AUTOSAR XML (schema 4-2-2)
package /STELLANTIS/EPT/ASWCs
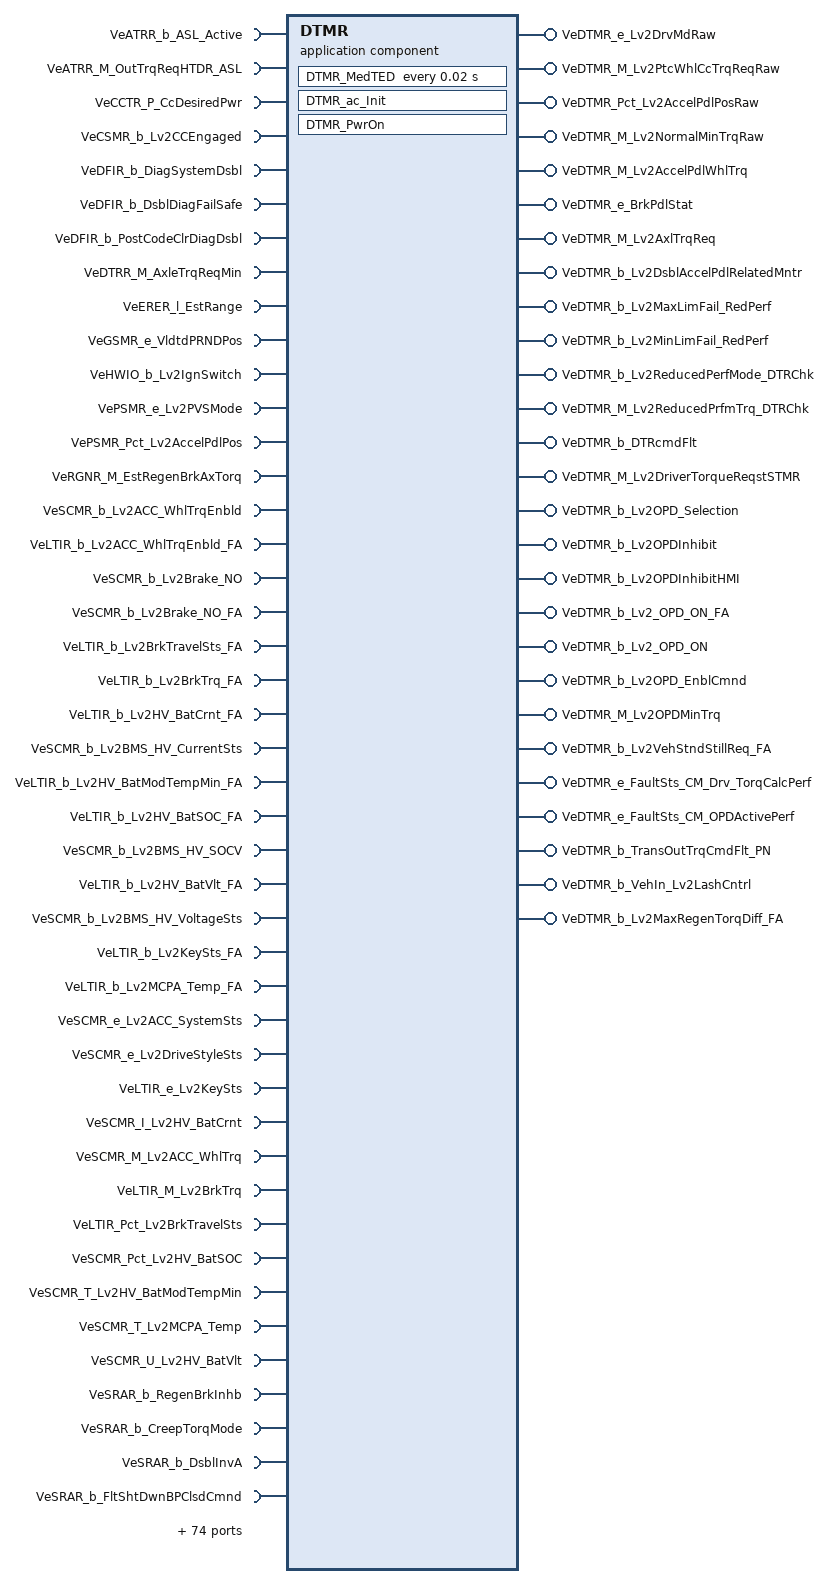
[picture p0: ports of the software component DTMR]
  application sw component type DTMR
    116 x require port:
      VeATRR_b_ASL_Active: nonqueued-receiver-com-spec{data-element=Value, init-value=0}, required-interface=VeATRR_b_ASL_Active
      VeATRR_M_OutTrqReqHTDR_ASL: nonqueued-receiver-com-spec{data-element=Value, init-value=0}, required-interface=VeATRR_M_OutTrqReqHTDR_ASL
      VeCCTR_P_CcDesiredPwr: nonqueued-receiver-com-spec{data-element=Value, init-value=0}, required-interface=VeCCTR_P_CcDesiredPwr
      VeCSMR_b_Lv2CCEngaged: nonqueued-receiver-com-spec{data-element=Value, init-value=0}, required-interface=VeCSMR_b_Lv2CCEngaged
      VeDFIR_b_DiagSystemDsbl: nonqueued-receiver-com-spec{data-element=Value, init-value=0}, required-interface=VeDFIR_b_DiagSystemDsbl
      VeDFIR_b_DsblDiagFailSafe: nonqueued-receiver-com-spec{data-element=Value, init-value=0}, required-interface=VeDFIR_b_DsblDiagFailSafe
      VeDFIR_b_PostCodeClrDiagDsbl: nonqueued-receiver-com-spec{data-element=Value, init-value=0}, required-interface=VeDFIR_b_PostCodeClrDiagDsbl
      VeDTRR_M_AxleTrqReqMin: nonqueued-receiver-com-spec{data-element=Value, init-value=0}, required-interface=VeDTRR_M_AxleTrqReqMin
      VeERER_l_EstRange: nonqueued-receiver-com-spec{data-element=Value, init-value=0}, required-interface=VeERER_l_EstRange
      VeGSMR_e_VldtdPRNDPos: variation-point={short-label=vpVeGSMR_e_VldtdPRNDPos, sw-syscond=1}, nonqueued-receiver-com-spec{data-element=Value, init-value=CeGSMR_e_TransRangePark}, required-interface=VeGSMR_e_VldtdPRNDPos
      VeHWIO_b_Lv2IgnSwitch: nonqueued-receiver-com-spec{data-element=Value, init-value=0}, required-interface=VeHWIO_b_Lv2IgnSwitch
      VePSMR_e_Lv2PVSMode: nonqueued-receiver-com-spec{data-element=Value, init-value=CePSMR_e_NO_Fault}, required-interface=VePSMR_e_Lv2PVSMode
      VePSMR_Pct_Lv2AccelPdlPos: nonqueued-receiver-com-spec{data-element=Value, init-value=0}, required-interface=VePSMR_Pct_Lv2AccelPdlPos
      VeRGNR_M_EstRegenBrkAxTorq: nonqueued-receiver-com-spec{data-element=Value, init-value=0}, required-interface=VeRGNR_M_EstRegenBrkAxTorq
      VeSCMR_b_Lv2ACC_WhlTrqEnbld: nonqueued-receiver-com-spec{data-element=Value, init-value=0}, required-interface=VeSCMR_b_Lv2ACC_WhlTrqEnbld
      VeLTIR_b_Lv2ACC_WhlTrqEnbld_FA: nonqueued-receiver-com-spec{data-element=Value, init-value=0}, required-interface=VeLTIR_b_Lv2ACC_WhlTrqEnbld_FA
      VeSCMR_b_Lv2Brake_NO: nonqueued-receiver-com-spec{data-element=Value, init-value=0}, required-interface=VeSCMR_b_Lv2Brake_NO
      VeSCMR_b_Lv2Brake_NO_FA: nonqueued-receiver-com-spec{data-element=Value, init-value=0}, required-interface=VeSCMR_b_Lv2Brake_NO_FA
      VeLTIR_b_Lv2BrkTravelSts_FA: nonqueued-receiver-com-spec{data-element=Value, init-value=0}, required-interface=VeLTIR_b_Lv2BrkTravelSts_FA
      VeLTIR_b_Lv2BrkTrq_FA: nonqueued-receiver-com-spec{data-element=Value, init-value=0}, required-interface=VeLTIR_b_Lv2BrkTrq_FA
      VeLTIR_b_Lv2HV_BatCrnt_FA: nonqueued-receiver-com-spec{data-element=Value, init-value=0}, required-interface=VeLTIR_b_Lv2HV_BatCrnt_FA
      VeSCMR_b_Lv2BMS_HV_CurrentSts: nonqueued-receiver-com-spec{data-element=Value, init-value=0}, required-interface=VeSCMR_b_Lv2BMS_HV_CurrentSts
      VeLTIR_b_Lv2HV_BatModTempMin_FA: nonqueued-receiver-com-spec{data-element=Value, init-value=0}, required-interface=VeLTIR_b_Lv2HV_BatModTempMin_FA
      VeLTIR_b_Lv2HV_BatSOC_FA: nonqueued-receiver-com-spec{data-element=Value, init-value=0}, required-interface=VeLTIR_b_Lv2HV_BatSOC_FA
      VeSCMR_b_Lv2BMS_HV_SOCV: nonqueued-receiver-com-spec{data-element=Value, init-value=0}, required-interface=VeSCMR_b_Lv2BMS_HV_SOCV
      VeLTIR_b_Lv2HV_BatVlt_FA: nonqueued-receiver-com-spec{data-element=Value, init-value=0}, required-interface=VeLTIR_b_Lv2HV_BatVlt_FA
      VeSCMR_b_Lv2BMS_HV_VoltageSts: nonqueued-receiver-com-spec{data-element=Value, init-value=0}, required-interface=VeSCMR_b_Lv2BMS_HV_VoltageSts
      VeLTIR_b_Lv2KeySts_FA: nonqueued-receiver-com-spec{data-element=Value, init-value=0}, required-interface=VeLTIR_b_Lv2KeySts_FA
      VeLTIR_b_Lv2MCPA_Temp_FA: nonqueued-receiver-com-spec{data-element=Value, init-value=0}, required-interface=VeLTIR_b_Lv2MCPA_Temp_FA
      VeSCMR_e_Lv2ACC_SystemSts: nonqueued-receiver-com-spec{data-element=Value, init-value=CeSTMR_e_Off_M182}, required-interface=VeSCMR_e_Lv2ACC_SystemSts
      VeSCMR_e_Lv2DriveStyleSts: nonqueued-receiver-com-spec{data-element=Value, init-value=0}, required-interface=VeSCMR_e_Lv2DriveStyleSts
      VeLTIR_e_Lv2KeySts: nonqueued-receiver-com-spec{data-element=Value, init-value=CeLTIR_e_IGN_LK}, required-interface=VeLTIR_e_Lv2KeySts
      VeSCMR_I_Lv2HV_BatCrnt: nonqueued-receiver-com-spec{data-element=Value, init-value=0}, required-interface=VeSCMR_I_Lv2HV_BatCrnt
      VeSCMR_M_Lv2ACC_WhlTrq: nonqueued-receiver-com-spec{data-element=Value, init-value=0}, required-interface=VeSCMR_M_Lv2ACC_WhlTrq
      VeLTIR_M_Lv2BrkTrq: nonqueued-receiver-com-spec{data-element=Value, init-value=0}, required-interface=VeLTIR_M_Lv2BrkTrq
      VeLTIR_Pct_Lv2BrkTravelSts: nonqueued-receiver-com-spec{data-element=Value, init-value=0}, required-interface=VeLTIR_Pct_Lv2BrkTravelSts
      VeSCMR_Pct_Lv2HV_BatSOC: nonqueued-receiver-com-spec{data-element=Value, init-value=0}, required-interface=VeSCMR_Pct_Lv2HV_BatSOC
      VeSCMR_T_Lv2HV_BatModTempMin: nonqueued-receiver-com-spec{data-element=Value, init-value=0}, required-interface=VeSCMR_T_Lv2HV_BatModTempMin
      VeSCMR_T_Lv2MCPA_Temp: nonqueued-receiver-com-spec{data-element=Value, init-value=0}, required-interface=VeSCMR_T_Lv2MCPA_Temp
      VeSCMR_U_Lv2HV_BatVlt: nonqueued-receiver-com-spec{data-element=Value, init-value=0}, required-interface=VeSCMR_U_Lv2HV_BatVlt
      VeSRAR_b_RegenBrkInhb: nonqueued-receiver-com-spec{data-element=Value, init-value=0}, required-interface=VeSRAR_b_RegenBrkInhb
      VeSRAR_b_CreepTorqMode: nonqueued-receiver-com-spec{data-element=Value, init-value=0}, required-interface=VeSRAR_b_CreepTorqMode
      VeSRAR_b_DsblInvA: nonqueued-receiver-com-spec{data-element=Value, init-value=0}, required-interface=VeSRAR_b_DsblInvA
      VeSRAR_b_FltShtDwnBPClsdCmnd: nonqueued-receiver-com-spec{data-element=Value, init-value=0}, required-interface=VeSRAR_b_FltShtDwnBPClsdCmnd
      VeSRAR_b_FltShtDwnCmnd: nonqueued-receiver-com-spec{data-element=Value, init-value=0}, required-interface=VeSRAR_b_FltShtDwnCmnd
      VeSRAR_b_OpnBattCntctr: nonqueued-receiver-com-spec{data-element=Value, init-value=0}, required-interface=VeSRAR_b_OpnBattCntctr
      VeSRAR_b_ReducedPerfMode: nonqueued-receiver-com-spec{data-element=Value, init-value=0}, required-interface=VeSRAR_b_ReducedPerfMode
      VeSSMR_b_VehSpdFA: nonqueued-receiver-com-spec{data-element=Value, init-value=0}, required-interface=VeSSMR_b_VehSpdFA
      VeSSMR_v_VehSpd: nonqueued-receiver-com-spec{data-element=Value, init-value=0}, required-interface=VeSSMR_v_VehSpd
      VeSCCR_r_RipAWD: nonqueued-receiver-com-spec{data-element=Value, init-value=0}, required-interface=VeSCCR_r_RipAWD
      VeSCCR_b_PerfAWDFlag: nonqueued-receiver-com-spec{data-element=Value, init-value=0}, required-interface=VeSCCR_b_PerfAWDFlag
      VeSCCR_M_FrntAxlOLMin: nonqueued-receiver-com-spec{data-element=Value, init-value=0}, required-interface=VeSCCR_M_FrntAxlOLMin
      VeSCCR_M_FrntAxlOLMax: nonqueued-receiver-com-spec{data-element=Value, init-value=0}, required-interface=VeSCCR_M_FrntAxlOLMax
      VeSCCR_M_RrAxlOLMax: nonqueued-receiver-com-spec{data-element=Value, init-value=0}, required-interface=VeSCCR_M_RrAxlOLMax
      VeSCCR_M_RrAxlOLMin: nonqueued-receiver-com-spec{data-element=Value, init-value=0}, required-interface=VeSCCR_M_RrAxlOLMin
      VeSCMR_M_Lv2RegenBrkFrontOffsetRequest: nonqueued-receiver-com-spec{data-element=Value, init-value=0}, required-interface=VeSCMR_M_Lv2RegenBrkFrontOffsetRequest
      VeSCMR_M_Lv2RegenBrkRearOffsetRequest: nonqueued-receiver-com-spec{data-element=Value, init-value=0}, required-interface=VeSCMR_M_Lv2RegenBrkRearOffsetRequest
      VeSCMR_b_Lv2RegenBrkFrontOffsetRequestFA: nonqueued-receiver-com-spec{data-element=Value, init-value=0}, required-interface=VeSCMR_b_Lv2RegenBrkFrontOffsetRequestFA
      VeSCMR_b_Lv2RegenBrkRearOffsetRequestFA: nonqueued-receiver-com-spec{data-element=Value, init-value=0}, required-interface=VeSCMR_b_Lv2RegenBrkRearOffsetRequestFA
      VeSCMR_b_Lv2ESC_Active: nonqueued-receiver-com-spec{data-element=Value, init-value=0}, required-interface=VeSCMR_b_Lv2ESC_Active
      VeSCMR_b_Lv2ESC_FailSts: nonqueued-receiver-com-spec{data-element=Value, init-value=0}, required-interface=VeSCMR_b_Lv2ESC_FailSts
      VeDMIR_e_eCoastingSel: nonqueued-receiver-com-spec{data-element=Value, init-value=CeDMIR_e_Level1}, required-interface=VeDMIR_e_eCoastingSel
      VeSCMR_b_RegBrk_Active: nonqueued-receiver-com-spec{data-element=Value, init-value=0}, required-interface=VeSCMR_b_RegBrk_Active
      VeSCCR_r_RipRegen: nonqueued-receiver-com-spec{data-element=Value, init-value=0}, required-interface=VeSCCR_r_RipRegen
      VeVTVR_M_OptToFront: nonqueued-receiver-com-spec{data-element=Value, init-value=0}, required-interface=VeVTVR_M_OptToFront
      VeVTVR_M_OptToRear: nonqueued-receiver-com-spec{data-element=Value, init-value=0}, required-interface=VeVTVR_M_OptToRear
      VeATRR_M_OutputTorqReqImmedHTDR: nonqueued-receiver-com-spec{data-element=Value, init-value=0}, required-interface=VeATRR_M_OutputTorqReqImmedHTDR
      VeSTMR_b_Lv2STMR_ReducedPerfMode: nonqueued-receiver-com-spec{data-element=Value, init-value=0}, required-interface=VeSTMR_b_Lv2STMR_ReducedPerfMode
      VeSTMR_b_TransOutTrqCmdFlt: nonqueued-receiver-com-spec{data-element=Value, init-value=0}, required-interface=VeSTMR_b_TransOutTrqCmdFlt
      VeSTMR_b_RgnEstMntrFlt: nonqueued-receiver-com-spec{data-element=Value, init-value=0}, required-interface=VeSTMR_b_RgnEstMntrFlt
      VeSTMR_b_Lv2CruiseTrqChkFailed: nonqueued-receiver-com-spec{data-element=Value, init-value=0}, required-interface=VeSTMR_b_Lv2CruiseTrqChkFailed
      VeSTMR_b_TrqSplit_OS_US: nonqueued-receiver-com-spec{data-element=Value, init-value=0}, required-interface=VeSTMR_b_TrqSplit_OS_US
      VeSCMR_b_Lv2DriveStyleStsFA: variation-point={short-label=vpVeSCMR_b_Lv2DriveStyleStsFA, sw-syscond=1}, nonqueued-receiver-com-spec{data-element=Value, init-value=0}, required-interface=VeSCMR_b_Lv2DriveStyleStsFA
      VeLTIR_b_Lv2BrkMaxRgnReady_FA: variation-point={short-label=vpVeLTIR_b_Lv2BrkMaxRgnReady_FA, sw-syscond=1}, nonqueued-receiver-com-spec{data-element=Value, init-value=0}, required-interface=VeLTIR_b_Lv2BrkMaxRgnReady_FA
      VeSCMR_e_Lv2BrkMaxRgnReady: variation-point={short-label=vpVeSCMR_e_Lv2BrkMaxRgnReady, sw-syscond=1}, nonqueued-receiver-com-spec{data-element=Value, init-value=0}, required-interface=VeSCMR_e_Lv2BrkMaxRgnReady
      VeSRAR_b_OnePedalDriveDsbl: variation-point={short-label=vpVeSRAR_b_OnePedalDriveDsbl, sw-syscond=1}, nonqueued-receiver-com-spec{data-element=Value, init-value=0}, required-interface=VeSRAR_b_OnePedalDriveDsbl
      VeLTIR_b_Lv2MtrA_Spd_FA: variation-point={short-label=vpVeLTIR_b_Lv2MtrA_Spd_FA, sw-syscond=1}, nonqueued-receiver-com-spec{data-element=Value, init-value=0}, required-interface=VeLTIR_b_Lv2MtrA_Spd_FA
      VeDTRR_b_OPD_Active: variation-point={short-label=vpVeDTRR_b_OPD_Active, sw-syscond=1}, nonqueued-receiver-com-spec{data-element=Value, init-value=0}, required-interface=VeDTRR_b_OPD_Active
      VeDTRR_b_VehStndStillReq_OPD: variation-point={short-label=vpVeDTRR_b_VehStndStillReq_OPD, sw-syscond=1}, nonqueued-receiver-com-spec{data-element=Value, init-value=0}, required-interface=VeDTRR_b_VehStndStillReq_OPD
      VeLTIR_b_Lv2MtrB_Spd_FA: variation-point={short-label=vpVeLTIR_b_Lv2MtrB_Spd_FA, sw-syscond=1}, nonqueued-receiver-com-spec{data-element=Value, init-value=0}, required-interface=VeLTIR_b_Lv2MtrB_Spd_FA
      VeSCMR_e_Lv2EPB_HoldSts: nonqueued-receiver-com-spec{data-element=Value, init-value=CeSTMR_e_EPBHoldSts_REL}, required-interface=VeSCMR_e_Lv2EPB_HoldSts
      VeLTIR_b_Lv2EPB_HoldSts_FA: nonqueued-receiver-com-spec{data-element=Value, init-value=0}, required-interface=VeLTIR_b_Lv2EPB_HoldSts_FA
      VeHTDR_b_AHH_ModifyAccel_Req: nonqueued-receiver-com-spec{data-element=Value, init-value=0}, required-interface=VeHTDR_b_AHH_ModifyAccel_Req
      VeHTDR_e_AHH_ApplyRelease_Req: nonqueued-receiver-com-spec{data-element=Value, init-value=CeHTDR_e_AHH_Inactive}, required-interface=VeHTDR_e_AHH_ApplyRelease_Req
      VeLTIR_b_Lv2AHH_Ready_Status_FA: nonqueued-receiver-com-spec{data-element=Value, init-value=0}, required-interface=VeLTIR_b_Lv2AHH_Ready_Status_FA
      VeSCMR_e_Lv2AHH_Ready_Status: nonqueued-receiver-com-spec{data-element=Value, init-value=CeSTMR_e_AHH_NotReady}, required-interface=VeSCMR_e_Lv2AHH_Ready_Status
      VeGSMR_e_VldtdPRNDPosDR: nonqueued-receiver-com-spec{data-element=Value, init-value=CeGSMR_e_TransRangePark}, required-interface=VeGSMR_e_VldtdPRNDPosDR
      VeLTIR_M_Lv2BrkTrqDriver: nonqueued-receiver-com-spec{data-element=Value, init-value=0}, required-interface=VeLTIR_M_Lv2BrkTrqDriver
      VeLTIR_b_Lv2BrkTrqDriver_FA: nonqueued-receiver-com-spec{data-element=Value, init-value=0}, required-interface=VeLTIR_b_Lv2BrkTrqDriver_FA
      VeLTIR_b_Lv2RgnBrkAxTrqReq_FA: nonqueued-receiver-com-spec{data-element=Value, init-value=0}, required-interface=VeLTIR_b_Lv2RgnBrkAxTrqReq_FA
      VeSCMR_M_Lv2RgnBrkAxTrqReq: nonqueued-receiver-com-spec{data-element=Value, init-value=0}, required-interface=VeSCMR_M_Lv2RgnBrkAxTrqReq
      VePLTR_Pct_EstSlopeAnglePct: nonqueued-receiver-com-spec{data-element=Value, init-value=0}, required-interface=VePLTR_Pct_EstSlopeAnglePct
      VeSRAR_b_Inhibit_DriveMode: nonqueued-receiver-com-spec{data-element=Value, init-value=0}, required-interface=VeSRAR_b_Inhibit_DriveMode
      VeLTIR_M_Lv2MtrA_TrqCmnd: nonqueued-receiver-com-spec{data-element=Value, init-value=0}, required-interface=VeLTIR_M_Lv2MtrA_TrqCmnd
      VeHTDR_M_MtrB_TorqCmnd: nonqueued-receiver-com-spec{data-element=Value, init-value=0}, required-interface=VeHTDR_M_MtrB_TorqCmnd
      VeSCMR_M_Lv2MtrA_TrqAchieved: nonqueued-receiver-com-spec{data-element=Value, init-value=0}, required-interface=VeSCMR_M_Lv2MtrA_TrqAchieved
      VeSCMR_M_Lv2MtrB_TrqAchieved: nonqueued-receiver-com-spec{data-element=Value, init-value=0}, required-interface=VeSCMR_M_Lv2MtrB_TrqAchieved
      VeLTIR_p_Lv2BrakeBoostPressure: nonqueued-receiver-com-spec{data-element=Value, init-value=0}, required-interface=VeLTIR_p_Lv2BrakeBoostPressure
      VeSCMR_e_Lv2GlobDrvMdRq: variation-point={short-label=vpVeSCMR_e_Lv2GlobDrvMdRq, sw-syscond=1}, nonqueued-receiver-com-spec{data-element=Value, init-value=0}, required-interface=VeSCMR_e_Lv2GlobDrvMdRq
      VeLTIR_b_Lv2GlobDrvMdRq_FA: variation-point={short-label=vpVeLTIR_b_Lv2GlobDrvMdRq_FA, sw-syscond=1}, nonqueued-receiver-com-spec{data-element=Value, init-value=0}, required-interface=VeLTIR_b_Lv2GlobDrvMdRq_FA
      VeSCMR_e_Lv2GlobDrvMdRq_BCM: variation-point={short-label=vpVeSCMR_e_Lv2GlobDrvMdRq_BCM, sw-syscond=1}, nonqueued-receiver-com-spec{data-element=Value, init-value=0}, required-interface=VeSCMR_e_Lv2GlobDrvMdRq_BCM
      VeLTIR_b_Lv2GlobDrvMdRq_BCM_FA: variation-point={short-label=vpVeLTIR_b_Lv2GlobDrvMdRq_BCM_FA, sw-syscond=1}, nonqueued-receiver-com-spec{data-element=Value, init-value=0}, required-interface=VeLTIR_b_Lv2GlobDrvMdRq_BCM_FA
      VeTIMR_e_RaceModeSts: variation-point={short-label=vpVeTIMR_e_RaceModeSts, sw-syscond=1}, nonqueued-receiver-com-spec{data-element=Value, init-value=CeTIMR_e_RaceMode_Off}, required-interface=VeTIMR_e_RaceModeSts
      VeSRAR_b_Inhibit_AWD_TerrainMode: variation-point={short-label=vpVeSRAR_b_Inhibit_AWD_TerrainMode, sw-syscond=1}, nonqueued-receiver-com-spec{data-element=Value, init-value=0}, required-interface=VeSRAR_b_Inhibit_AWD_TerrainMode
      VeEBMR_e_eBoostStatus: variation-point={short-label=vpVeEBMR_e_eBoostStatus, sw-syscond=1}, nonqueued-receiver-com-spec{data-element=Value, init-value=CeEBMR_e_eBoostOFF}, required-interface=VeEBMR_e_eBoostStatus
      VeSCMR_e_Lv2Trns_DrvMdReq: variation-point={short-label=vpVeSCMR_e_Lv2Trns_DrvMdReq, sw-syscond=1}, nonqueued-receiver-com-spec{data-element=Value, init-value=0}, required-interface=VeSCMR_e_Lv2Trns_DrvMdReq
      VeLTIR_b_Lv2Trns_DrvMdReq_FA: variation-point={short-label=vpVeLTIR_b_Lv2Trns_DrvMdReq_FA, sw-syscond=1}, nonqueued-receiver-com-spec{data-element=Value, init-value=0}, required-interface=VeLTIR_b_Lv2Trns_DrvMdReq_FA
      VeDMDR_e_DrvMdArb: variation-point={short-label=vpVeDMDR_e_DrvMdArb, sw-syscond=1}, nonqueued-receiver-com-spec{data-element=Value, init-value=CeDMDR_e_NoDrvMd}, required-interface=VeDMDR_e_DrvMdArb
      VeDMIR_e_RegenSts: variation-point={short-label=vpVeDMIR_e_RegenSts, sw-syscond=1}, nonqueued-receiver-com-spec{data-element=Value, init-value=CeDMIR_e_NormalRegen}, required-interface=VeDMIR_e_RegenSts
      VeWTAR_M_AeCoastTorqDiff: nonqueued-receiver-com-spec{data-element=Value, init-value=0}, required-interface=VeWTAR_M_AeCoastTorqDiff
      VeSRMR_e_LimitationMd: variation-point={short-label=vpVeSRMR_e_LimitationMd, sw-syscond=1}, nonqueued-receiver-com-spec{data-element=Value, init-value=CeSRMR_e_NoLimitation}, required-interface=VeSRMR_e_LimitationMd
      VeLTIR_b_Lv2ACC_WhlTrq_ADAS_FA: nonqueued-receiver-com-spec{data-element=Value, init-value=0}, required-interface=VeLTIR_b_Lv2ACC_WhlTrq_ADAS_FA
      VeSCMR_M_Lv2ACC_WhlTrq_ADAS: nonqueued-receiver-com-spec{data-element=Value, init-value=0}, required-interface=VeSCMR_M_Lv2ACC_WhlTrq_ADAS
      VeDMAB_y_StatusByte_CM_Drv_TorqCalcPerf: nonqueued-receiver-com-spec{data-element=Value, init-value=0}, required-interface=VeDMAB_y_StatusByte_CM_Drv_TorqCalcPerf
      VeDMIR_e_CreepSts: variation-point={short-label=vpVeDMIR_e_CreepSts, sw-syscond=1}, nonqueued-receiver-com-spec{data-element=Value, init-value=CeDMIR_e_CreepOff}, required-interface=VeDMIR_e_CreepSts
      VeATRR_M_OutputTorqReqPot: nonqueued-receiver-com-spec{data-element=Value, init-value=0}, required-interface=VeATRR_M_OutputTorqReqPot
    27 x provide port:
      VeDTMR_e_Lv2DrvMdRaw: nonqueued-sender-com-spec{data-element=Value, init-value=CeSTMR_e_DrvMdM182_Auto}, provided-interface=VeDTMR_e_Lv2DrvMdRaw
      VeDTMR_M_Lv2PtcWhlCcTrqReqRaw: nonqueued-sender-com-spec{data-element=Value, init-value=0}, provided-interface=VeDTMR_M_Lv2PtcWhlCcTrqReqRaw
      VeDTMR_Pct_Lv2AccelPdlPosRaw: nonqueued-sender-com-spec{data-element=Value, init-value=0}, provided-interface=VeDTMR_Pct_Lv2AccelPdlPosRaw
      VeDTMR_M_Lv2NormalMinTrqRaw: nonqueued-sender-com-spec{data-element=Value, init-value=0}, provided-interface=VeDTMR_M_Lv2NormalMinTrqRaw
      VeDTMR_M_Lv2AccelPdlWhlTrq: nonqueued-sender-com-spec{data-element=Value, init-value=0}, provided-interface=VeDTMR_M_Lv2AccelPdlWhlTrq
      VeDTMR_e_BrkPdlStat: nonqueued-sender-com-spec{data-element=Value, init-value=CeSTMR_e_BrkStat_NotDtrmnd}, provided-interface=VeDTMR_e_BrkPdlStat
      VeDTMR_M_Lv2AxlTrqReq: nonqueued-sender-com-spec{data-element=Value, init-value=0}, provided-interface=VeDTMR_M_Lv2AxlTrqReq
      VeDTMR_b_Lv2DsblAccelPdlRelatedMntr: nonqueued-sender-com-spec{data-element=Value, init-value=0}, provided-interface=VeDTMR_b_Lv2DsblAccelPdlRelatedMntr
      VeDTMR_b_Lv2MaxLimFail_RedPerf: nonqueued-sender-com-spec{data-element=Value, init-value=0}, provided-interface=VeDTMR_b_Lv2MaxLimFail_RedPerf
      VeDTMR_b_Lv2MinLimFail_RedPerf: nonqueued-sender-com-spec{data-element=Value, init-value=0}, provided-interface=VeDTMR_b_Lv2MinLimFail_RedPerf
      VeDTMR_b_Lv2ReducedPerfMode_DTRChk: nonqueued-sender-com-spec{data-element=Value, init-value=0}, provided-interface=VeDTMR_b_Lv2ReducedPerfMode_DTRChk
      VeDTMR_M_Lv2ReducedPrfmTrq_DTRChk: nonqueued-sender-com-spec{data-element=Value, init-value=0}, provided-interface=VeDTMR_M_Lv2ReducedPrfmTrq_DTRChk
      VeDTMR_b_DTRcmdFlt: nonqueued-sender-com-spec{data-element=Value, init-value=0}, provided-interface=VeDTMR_b_DTRcmdFlt
      VeDTMR_M_Lv2DriverTorqueReqstSTMR: nonqueued-sender-com-spec{data-element=Value, init-value=0}, provided-interface=VeDTMR_M_Lv2DriverTorqueReqstSTMR
      VeDTMR_b_Lv2OPD_Selection: nonqueued-sender-com-spec{data-element=Value, init-value=0}, provided-interface=VeDTMR_b_Lv2OPD_Selection
      VeDTMR_b_Lv2OPDInhibit: nonqueued-sender-com-spec{data-element=Value, init-value=0}, provided-interface=VeDTMR_b_Lv2OPDInhibit
      VeDTMR_b_Lv2OPDInhibitHMI: nonqueued-sender-com-spec{data-element=Value, init-value=0}, provided-interface=VeDTMR_b_Lv2OPDInhibitHMI
      VeDTMR_b_Lv2_OPD_ON_FA: nonqueued-sender-com-spec{data-element=Value, init-value=0}, provided-interface=VeDTMR_b_Lv2_OPD_ON_FA
      VeDTMR_b_Lv2_OPD_ON: nonqueued-sender-com-spec{data-element=Value, init-value=0}, provided-interface=VeDTMR_b_Lv2_OPD_ON
      VeDTMR_b_Lv2OPD_EnblCmnd: nonqueued-sender-com-spec{data-element=Value, init-value=0}, provided-interface=VeDTMR_b_Lv2OPD_EnblCmnd
      VeDTMR_M_Lv2OPDMinTrq: nonqueued-sender-com-spec{data-element=Value, init-value=0}, provided-interface=VeDTMR_M_Lv2OPDMinTrq
      VeDTMR_b_Lv2VehStndStillReq_FA: nonqueued-sender-com-spec{data-element=Value, init-value=0}, provided-interface=VeDTMR_b_Lv2VehStndStillReq_FA
      VeDTMR_e_FaultSts_CM_Drv_TorqCalcPerf: nonqueued-sender-com-spec{data-element=Value, init-value=CeDFIB_e_Init}, provided-interface=VeDTMR_e_FaultSts_CM_Drv_TorqCalcPerf
      VeDTMR_e_FaultSts_CM_OPDActivePerf: nonqueued-sender-com-spec{data-element=Value, init-value=CeDFIB_e_Init}, provided-interface=VeDTMR_e_FaultSts_CM_OPDActivePerf
      VeDTMR_b_TransOutTrqCmdFlt_PN: nonqueued-sender-com-spec{data-element=Value, init-value=0}, provided-interface=VeDTMR_b_TransOutTrqCmdFlt_PN
      VeDTMR_b_VehIn_Lv2LashCntrl: nonqueued-sender-com-spec{data-element=Value, init-value=0}, provided-interface=VeDTMR_b_VehIn_Lv2LashCntrl
      VeDTMR_b_Lv2MaxRegenTorqDiff_FA: nonqueued-sender-com-spec{data-element=Value, init-value=0}, provided-interface=VeDTMR_b_Lv2MaxRegenTorqDiff_FA
    require port DTMR_FastTEF_StartCheckpoint: client-com-spec=CheckpointReached, required-interface=WdgM_LocalSupervision
    require port DTMR_FastTEF_StopCheckpoint: client-com-spec=CheckpointReached, required-interface=WdgM_LocalSupervision
    behavior IB_DTMR: data-type-mapping=msADTtoIDTMapping, handle-termination-and-restart=NO-SUPPORT, included-data-type-set=data-type=[TeDTMR_e_Lv2BrkPdlStat, TeDTMR_e_Lv2DrvMd_Total]
      timing event Event_MedTED: start-on-event=DTMR_MedTED, period=0.02
      init event Event_DTMR_ac_Init: start-on-event=DTMR_ac_Init
      init event Event_PwrOn: start-on-event=DTMR_PwrOn
      runnable DTMR_ac_Init
        data-send-points:
          4 x access:
            OUT_VeDTMR_e_Lv2DrvMdRaw_Value: accessed-variable=VeDTMR_e_Lv2DrvMdRaw.Value
            OUT_VeDTMR_e_BrkPdlStat_Value: accessed-variable=VeDTMR_e_BrkPdlStat.Value
            OUT_VeDTMR_e_FaultSts_CM_Drv_TorqCalcPerf_Value: accessed-variable=VeDTMR_e_FaultSts_CM_Drv_TorqCalcPerf.Value
            OUT_VeDTMR_e_FaultSts_CM_OPDActivePerf_Value: accessed-variable=VeDTMR_e_FaultSts_CM_OPDActivePerf.Value
      runnable DTMR_MedTED
        data-receive-point-by-arguments:
          115 x access:
            IN_VeATRR_M_OutTrqReqHTDR_ASL_Value: accessed-variable=VeATRR_M_OutTrqReqHTDR_ASL.Value
            IN_VeATRR_M_OutputTorqReqImmedHTDR_Value: accessed-variable=VeATRR_M_OutputTorqReqImmedHTDR.Value
            IN_VeATRR_M_OutputTorqReqPot_Value: accessed-variable=VeATRR_M_OutputTorqReqPot.Value
            IN_VeATRR_b_ASL_Active_Value: accessed-variable=VeATRR_b_ASL_Active.Value
            IN_VeCCTR_P_CcDesiredPwr_Value: accessed-variable=VeCCTR_P_CcDesiredPwr.Value
            IN_VeCSMR_b_Lv2CCEngaged_Value: accessed-variable=VeCSMR_b_Lv2CCEngaged.Value
            IN_VeDFIR_b_DiagSystemDsbl_Value: accessed-variable=VeDFIR_b_DiagSystemDsbl.Value
            IN_VeDFIR_b_DsblDiagFailSafe_Value: accessed-variable=VeDFIR_b_DsblDiagFailSafe.Value
            IN_VeDFIR_b_PostCodeClrDiagDsbl_Value: accessed-variable=VeDFIR_b_PostCodeClrDiagDsbl.Value
            IN_VeDMAB_y_StatusByte_CM_Drv_TorqCalcPerf_Value: accessed-variable=VeDMAB_y_StatusByte_CM_Drv_TorqCalcPerf.Value
            IN_VeDMDR_e_DrvMdArb_Value: accessed-variable=VeDMDR_e_DrvMdArb.Value, variation-point={short-label=vpIN_VeDMDR_e_DrvMdArb_Value, sw-syscond=1}
            IN_VeDMIR_e_CreepSts_Value: accessed-variable=VeDMIR_e_CreepSts.Value, variation-point={short-label=vpIN_VeDMIR_e_CreepSts_Value, sw-syscond=1}
            IN_VeDMIR_e_RegenSts_Value: accessed-variable=VeDMIR_e_RegenSts.Value, variation-point={short-label=vpIN_VeDMIR_e_RegenSts_Value, sw-syscond=1}
            IN_VeDMIR_e_eCoastingSel_Value: accessed-variable=VeDMIR_e_eCoastingSel.Value
            IN_VeDTRR_M_AxleTrqReqMin_Value: accessed-variable=VeDTRR_M_AxleTrqReqMin.Value
            IN_VeDTRR_b_OPD_Active_Value: accessed-variable=VeDTRR_b_OPD_Active.Value, variation-point={short-label=vpIN_VeDTRR_b_OPD_Active_Value, sw-syscond=1}
            IN_VeDTRR_b_VehStndStillReq_OPD_Value: accessed-variable=VeDTRR_b_VehStndStillReq_OPD.Value, variation-point={short-label=vpIN_VeDTRR_b_VehStndStillReq_OPD_Value, sw-syscond=1}
            IN_VeEBMR_e_eBoostStatus_Value: accessed-variable=VeEBMR_e_eBoostStatus.Value, variation-point={short-label=vpIN_VeEBMR_e_eBoostStatus_Value, sw-syscond=1}
            IN_VeERER_l_EstRange_Value: accessed-variable=VeERER_l_EstRange.Value
            IN_VeGSMR_e_VldtdPRNDPos_Value: accessed-variable=VeGSMR_e_VldtdPRNDPos.Value, variation-point={short-label=vpIN_VeGSMR_e_VldtdPRNDPos_Value, sw-syscond=1}
            IN_VeGSMR_e_VldtdPRNDPosDR_Value: accessed-variable=VeGSMR_e_VldtdPRNDPosDR.Value
            IN_VeHTDR_M_MtrB_TorqCmnd_Value: accessed-variable=VeHTDR_M_MtrB_TorqCmnd.Value
            IN_VeHTDR_b_AHH_ModifyAccel_Req_Value: accessed-variable=VeHTDR_b_AHH_ModifyAccel_Req.Value
            IN_VeHTDR_e_AHH_ApplyRelease_Req_Value: accessed-variable=VeHTDR_e_AHH_ApplyRelease_Req.Value
            IN_VeHWIO_b_Lv2IgnSwitch_Value: accessed-variable=VeHWIO_b_Lv2IgnSwitch.Value
            IN_VeLTIR_M_Lv2BrkTrq_Value: accessed-variable=VeLTIR_M_Lv2BrkTrq.Value
            IN_VeLTIR_M_Lv2BrkTrqDriver_Value: accessed-variable=VeLTIR_M_Lv2BrkTrqDriver.Value
            IN_VeLTIR_M_Lv2MtrA_TrqCmnd_Value: accessed-variable=VeLTIR_M_Lv2MtrA_TrqCmnd.Value
            IN_VeLTIR_Pct_Lv2BrkTravelSts_Value: accessed-variable=VeLTIR_Pct_Lv2BrkTravelSts.Value
            IN_VeLTIR_b_Lv2ACC_WhlTrqEnbld_FA_Value: accessed-variable=VeLTIR_b_Lv2ACC_WhlTrqEnbld_FA.Value
            IN_VeLTIR_b_Lv2ACC_WhlTrq_ADAS_FA_Value: accessed-variable=VeLTIR_b_Lv2ACC_WhlTrq_ADAS_FA.Value
            IN_VeLTIR_b_Lv2AHH_Ready_Status_FA_Value: accessed-variable=VeLTIR_b_Lv2AHH_Ready_Status_FA.Value
            IN_VeLTIR_b_Lv2BrkMaxRgnReady_FA_Value: accessed-variable=VeLTIR_b_Lv2BrkMaxRgnReady_FA.Value, variation-point={short-label=vpIN_VeLTIR_b_Lv2BrkMaxRgnReady_FA_Value, sw-syscond=1}
            IN_VeLTIR_b_Lv2BrkTravelSts_FA_Value: accessed-variable=VeLTIR_b_Lv2BrkTravelSts_FA.Value
            IN_VeLTIR_b_Lv2BrkTrqDriver_FA_Value: accessed-variable=VeLTIR_b_Lv2BrkTrqDriver_FA.Value
            IN_VeLTIR_b_Lv2BrkTrq_FA_Value: accessed-variable=VeLTIR_b_Lv2BrkTrq_FA.Value
            IN_VeLTIR_b_Lv2EPB_HoldSts_FA_Value: accessed-variable=VeLTIR_b_Lv2EPB_HoldSts_FA.Value
            IN_VeLTIR_b_Lv2GlobDrvMdRq_BCM_FA_Value: accessed-variable=VeLTIR_b_Lv2GlobDrvMdRq_BCM_FA.Value, variation-point={short-label=vpIN_VeLTIR_b_Lv2GlobDrvMdRq_BCM_FA_Value, sw-syscond=1}
            IN_VeLTIR_b_Lv2GlobDrvMdRq_FA_Value: accessed-variable=VeLTIR_b_Lv2GlobDrvMdRq_FA.Value, variation-point={short-label=vpIN_VeLTIR_b_Lv2GlobDrvMdRq_FA_Value, sw-syscond=1}
            IN_VeLTIR_b_Lv2HV_BatCrnt_FA_Value: accessed-variable=VeLTIR_b_Lv2HV_BatCrnt_FA.Value
            IN_VeLTIR_b_Lv2HV_BatModTempMin_FA_Value: accessed-variable=VeLTIR_b_Lv2HV_BatModTempMin_FA.Value
            IN_VeLTIR_b_Lv2HV_BatSOC_FA_Value: accessed-variable=VeLTIR_b_Lv2HV_BatSOC_FA.Value
            IN_VeLTIR_b_Lv2HV_BatVlt_FA_Value: accessed-variable=VeLTIR_b_Lv2HV_BatVlt_FA.Value
            IN_VeLTIR_b_Lv2KeySts_FA_Value: accessed-variable=VeLTIR_b_Lv2KeySts_FA.Value
            IN_VeLTIR_b_Lv2MCPA_Temp_FA_Value: accessed-variable=VeLTIR_b_Lv2MCPA_Temp_FA.Value
            IN_VeLTIR_b_Lv2MtrA_Spd_FA_Value: accessed-variable=VeLTIR_b_Lv2MtrA_Spd_FA.Value, variation-point={short-label=vpIN_VeLTIR_b_Lv2MtrA_Spd_FA_Value, sw-syscond=1}
            IN_VeLTIR_b_Lv2MtrB_Spd_FA_Value: accessed-variable=VeLTIR_b_Lv2MtrB_Spd_FA.Value, variation-point={short-label=vpIN_VeLTIR_b_Lv2MtrB_Spd_FA_Value, sw-syscond=1}
            IN_VeLTIR_b_Lv2RgnBrkAxTrqReq_FA_Value: accessed-variable=VeLTIR_b_Lv2RgnBrkAxTrqReq_FA.Value
            IN_VeLTIR_b_Lv2Trns_DrvMdReq_FA_Value: accessed-variable=VeLTIR_b_Lv2Trns_DrvMdReq_FA.Value, variation-point={short-label=vpIN_VeLTIR_b_Lv2Trns_DrvMdReq_FA_Value, sw-syscond=1}
            IN_VeLTIR_e_Lv2KeySts_Value: accessed-variable=VeLTIR_e_Lv2KeySts.Value
            IN_VeLTIR_p_Lv2BrakeBoostPressure_Value: accessed-variable=VeLTIR_p_Lv2BrakeBoostPressure.Value
            IN_VePLTR_Pct_EstSlopeAnglePct_Value: accessed-variable=VePLTR_Pct_EstSlopeAnglePct.Value
            IN_VePSMR_Pct_Lv2AccelPdlPos_Value: accessed-variable=VePSMR_Pct_Lv2AccelPdlPos.Value
            IN_VePSMR_e_Lv2PVSMode_Value: accessed-variable=VePSMR_e_Lv2PVSMode.Value
            IN_VeRGNR_M_EstRegenBrkAxTorq_Value: accessed-variable=VeRGNR_M_EstRegenBrkAxTorq.Value
            IN_VeSCCR_M_FrntAxlOLMax_Value: accessed-variable=VeSCCR_M_FrntAxlOLMax.Value
            IN_VeSCCR_M_FrntAxlOLMin_Value: accessed-variable=VeSCCR_M_FrntAxlOLMin.Value
            IN_VeSCCR_M_RrAxlOLMax_Value: accessed-variable=VeSCCR_M_RrAxlOLMax.Value
            IN_VeSCCR_M_RrAxlOLMin_Value: accessed-variable=VeSCCR_M_RrAxlOLMin.Value
            IN_VeSCCR_b_PerfAWDFlag_Value: accessed-variable=VeSCCR_b_PerfAWDFlag.Value
            IN_VeSCCR_r_RipAWD_Value: accessed-variable=VeSCCR_r_RipAWD.Value
            IN_VeSCCR_r_RipRegen_Value: accessed-variable=VeSCCR_r_RipRegen.Value
            IN_VeSCMR_I_Lv2HV_BatCrnt_Value: accessed-variable=VeSCMR_I_Lv2HV_BatCrnt.Value
            IN_VeSCMR_M_Lv2ACC_WhlTrq_Value: accessed-variable=VeSCMR_M_Lv2ACC_WhlTrq.Value
            IN_VeSCMR_M_Lv2ACC_WhlTrq_ADAS_Value: accessed-variable=VeSCMR_M_Lv2ACC_WhlTrq_ADAS.Value
            IN_VeSCMR_M_Lv2MtrA_TrqAchieved_Value: accessed-variable=VeSCMR_M_Lv2MtrA_TrqAchieved.Value
            IN_VeSCMR_M_Lv2MtrB_TrqAchieved_Value: accessed-variable=VeSCMR_M_Lv2MtrB_TrqAchieved.Value
            IN_VeSCMR_M_Lv2RegenBrkFrontOffsetRequest_Value: accessed-variable=VeSCMR_M_Lv2RegenBrkFrontOffsetRequest.Value
            IN_VeSCMR_M_Lv2RegenBrkRearOffsetRequest_Value: accessed-variable=VeSCMR_M_Lv2RegenBrkRearOffsetRequest.Value
            IN_VeSCMR_M_Lv2RgnBrkAxTrqReq_Value: accessed-variable=VeSCMR_M_Lv2RgnBrkAxTrqReq.Value
            IN_VeSCMR_Pct_Lv2HV_BatSOC_Value: accessed-variable=VeSCMR_Pct_Lv2HV_BatSOC.Value
            IN_VeSCMR_T_Lv2HV_BatModTempMin_Value: accessed-variable=VeSCMR_T_Lv2HV_BatModTempMin.Value
            IN_VeSCMR_T_Lv2MCPA_Temp_Value: accessed-variable=VeSCMR_T_Lv2MCPA_Temp.Value
            IN_VeSCMR_U_Lv2HV_BatVlt_Value: accessed-variable=VeSCMR_U_Lv2HV_BatVlt.Value
            IN_VeSCMR_b_Lv2ACC_WhlTrqEnbld_Value: accessed-variable=VeSCMR_b_Lv2ACC_WhlTrqEnbld.Value
            IN_VeSCMR_b_Lv2BMS_HV_CurrentSts_Value: accessed-variable=VeSCMR_b_Lv2BMS_HV_CurrentSts.Value
            IN_VeSCMR_b_Lv2BMS_HV_SOCV_Value: accessed-variable=VeSCMR_b_Lv2BMS_HV_SOCV.Value
            IN_VeSCMR_b_Lv2BMS_HV_VoltageSts_Value: accessed-variable=VeSCMR_b_Lv2BMS_HV_VoltageSts.Value
            IN_VeSCMR_b_Lv2Brake_NO_Value: accessed-variable=VeSCMR_b_Lv2Brake_NO.Value
            IN_VeSCMR_b_Lv2Brake_NO_FA_Value: accessed-variable=VeSCMR_b_Lv2Brake_NO_FA.Value
            IN_VeSCMR_b_Lv2DriveStyleStsFA_Value: accessed-variable=VeSCMR_b_Lv2DriveStyleStsFA.Value, variation-point={short-label=vpIN_VeSCMR_b_Lv2DriveStyleStsFA_Value, sw-syscond=1}
            IN_VeSCMR_b_Lv2ESC_Active_Value: accessed-variable=VeSCMR_b_Lv2ESC_Active.Value
            IN_VeSCMR_b_Lv2ESC_FailSts_Value: accessed-variable=VeSCMR_b_Lv2ESC_FailSts.Value
            IN_VeSCMR_b_Lv2RegenBrkFrontOffsetRequestFA_Value: accessed-variable=VeSCMR_b_Lv2RegenBrkFrontOffsetRequestFA.Value
            IN_VeSCMR_b_Lv2RegenBrkRearOffsetRequestFA_Value: accessed-variable=VeSCMR_b_Lv2RegenBrkRearOffsetRequestFA.Value
            IN_VeSCMR_e_Lv2ACC_SystemSts_Value: accessed-variable=VeSCMR_e_Lv2ACC_SystemSts.Value
            IN_VeSCMR_e_Lv2AHH_Ready_Status_Value: accessed-variable=VeSCMR_e_Lv2AHH_Ready_Status.Value
            IN_VeSCMR_e_Lv2BrkMaxRgnReady_Value: accessed-variable=VeSCMR_e_Lv2BrkMaxRgnReady.Value, variation-point={short-label=vpIN_VeSCMR_e_Lv2BrkMaxRgnReady_Value, sw-syscond=1}
            IN_VeSCMR_e_Lv2DriveStyleSts_Value: accessed-variable=VeSCMR_e_Lv2DriveStyleSts.Value
            IN_VeSCMR_e_Lv2EPB_HoldSts_Value: accessed-variable=VeSCMR_e_Lv2EPB_HoldSts.Value
            IN_VeSCMR_e_Lv2GlobDrvMdRq_Value: accessed-variable=VeSCMR_e_Lv2GlobDrvMdRq.Value, variation-point={short-label=vpIN_VeSCMR_e_Lv2GlobDrvMdRq_Value, sw-syscond=1}
            IN_VeSCMR_e_Lv2GlobDrvMdRq_BCM_Value: accessed-variable=VeSCMR_e_Lv2GlobDrvMdRq_BCM.Value, variation-point={short-label=vpIN_VeSCMR_e_Lv2GlobDrvMdRq_BCM_Value, sw-syscond=1}
            IN_VeSCMR_e_Lv2Trns_DrvMdReq_Value: accessed-variable=VeSCMR_e_Lv2Trns_DrvMdReq.Value, variation-point={short-label=vpIN_VeSCMR_e_Lv2Trns_DrvMdReq_Value, sw-syscond=1}
            IN_VeSRAR_b_CreepTorqMode_Value: accessed-variable=VeSRAR_b_CreepTorqMode.Value
            IN_VeSRAR_b_DsblInvA_Value: accessed-variable=VeSRAR_b_DsblInvA.Value
            IN_VeSRAR_b_FltShtDwnBPClsdCmnd_Value: accessed-variable=VeSRAR_b_FltShtDwnBPClsdCmnd.Value
            IN_VeSRAR_b_FltShtDwnCmnd_Value: accessed-variable=VeSRAR_b_FltShtDwnCmnd.Value
            IN_VeSRAR_b_Inhibit_AWD_TerrainMode_Value: accessed-variable=VeSRAR_b_Inhibit_AWD_TerrainMode.Value, variation-point={short-label=vpIN_VeSRAR_b_Inhibit_AWD_TerrainMode_Value, sw-syscond=1}
            IN_VeSRAR_b_Inhibit_DriveMode_Value: accessed-variable=VeSRAR_b_Inhibit_DriveMode.Value
            IN_VeSRAR_b_OnePedalDriveDsbl_Value: accessed-variable=VeSRAR_b_OnePedalDriveDsbl.Value, variation-point={short-label=vpIN_VeSRAR_b_OnePedalDriveDsbl_Value, sw-syscond=1}
            IN_VeSRAR_b_OpnBattCntctr_Value: accessed-variable=VeSRAR_b_OpnBattCntctr.Value
            IN_VeSRAR_b_ReducedPerfMode_Value: accessed-variable=VeSRAR_b_ReducedPerfMode.Value
            IN_VeSRAR_b_RegenBrkInhb_Value: accessed-variable=VeSRAR_b_RegenBrkInhb.Value
            IN_VeSRMR_e_LimitationMd_Value: accessed-variable=VeSRMR_e_LimitationMd.Value, variation-point={short-label=vpIN_VeSRMR_e_LimitationMd_Value, sw-syscond=1}
            IN_VeSSMR_b_VehSpdFA_Value: accessed-variable=VeSSMR_b_VehSpdFA.Value
            IN_VeSSMR_v_VehSpd_Value: accessed-variable=VeSSMR_v_VehSpd.Value
            IN_VeSTMR_b_Lv2CruiseTrqChkFailed_Value: accessed-variable=VeSTMR_b_Lv2CruiseTrqChkFailed.Value
            IN_VeSTMR_b_Lv2STMR_ReducedPerfMode_Value: accessed-variable=VeSTMR_b_Lv2STMR_ReducedPerfMode.Value
            IN_VeSTMR_b_RgnEstMntrFlt_Value: accessed-variable=VeSTMR_b_RgnEstMntrFlt.Value
            IN_VeSTMR_b_TransOutTrqCmdFlt_Value: accessed-variable=VeSTMR_b_TransOutTrqCmdFlt.Value
            IN_VeSTMR_b_TrqSplit_OS_US_Value: accessed-variable=VeSTMR_b_TrqSplit_OS_US.Value
            IN_VeTIMR_e_RaceModeSts_Value: accessed-variable=VeTIMR_e_RaceModeSts.Value, variation-point={short-label=vpIN_VeTIMR_e_RaceModeSts_Value, sw-syscond=1}
            IN_VeVTVR_M_OptToFront_Value: accessed-variable=VeVTVR_M_OptToFront.Value
            IN_VeVTVR_M_OptToRear_Value: accessed-variable=VeVTVR_M_OptToRear.Value
            IN_VeWTAR_M_AeCoastTorqDiff_Value: accessed-variable=VeWTAR_M_AeCoastTorqDiff.Value
        data-send-points:
          27 x access:
            OUT_VeDTMR_M_Lv2AccelPdlWhlTrq_Value: accessed-variable=VeDTMR_M_Lv2AccelPdlWhlTrq.Value
            OUT_VeDTMR_M_Lv2AxlTrqReq_Value: accessed-variable=VeDTMR_M_Lv2AxlTrqReq.Value
            OUT_VeDTMR_b_Lv2DsblAccelPdlRelatedMntr_Value: accessed-variable=VeDTMR_b_Lv2DsblAccelPdlRelatedMntr.Value
            OUT_VeDTMR_b_Lv2MaxLimFail_RedPerf_Value: accessed-variable=VeDTMR_b_Lv2MaxLimFail_RedPerf.Value
            OUT_VeDTMR_b_Lv2MinLimFail_RedPerf_Value: accessed-variable=VeDTMR_b_Lv2MinLimFail_RedPerf.Value
            OUT_VeDTMR_b_Lv2ReducedPerfMode_DTRChk_Value: accessed-variable=VeDTMR_b_Lv2ReducedPerfMode_DTRChk.Value
            OUT_VeDTMR_M_Lv2ReducedPrfmTrq_DTRChk_Value: accessed-variable=VeDTMR_M_Lv2ReducedPrfmTrq_DTRChk.Value
            OUT_VeDTMR_b_DTRcmdFlt_Value: accessed-variable=VeDTMR_b_DTRcmdFlt.Value
            OUT_VeDTMR_M_Lv2DriverTorqueReqstSTMR_Value: accessed-variable=VeDTMR_M_Lv2DriverTorqueReqstSTMR.Value
            OUT_VeDTMR_b_Lv2OPD_Selection_Value: accessed-variable=VeDTMR_b_Lv2OPD_Selection.Value
            OUT_VeDTMR_b_Lv2OPDInhibit_Value: accessed-variable=VeDTMR_b_Lv2OPDInhibit.Value
            OUT_VeDTMR_b_Lv2OPDInhibitHMI_Value: accessed-variable=VeDTMR_b_Lv2OPDInhibitHMI.Value
            OUT_VeDTMR_b_Lv2_OPD_ON_FA_Value: accessed-variable=VeDTMR_b_Lv2_OPD_ON_FA.Value
            OUT_VeDTMR_b_Lv2_OPD_ON_Value: accessed-variable=VeDTMR_b_Lv2_OPD_ON.Value
            OUT_VeDTMR_b_Lv2OPD_EnblCmnd_Value: accessed-variable=VeDTMR_b_Lv2OPD_EnblCmnd.Value
            OUT_VeDTMR_M_Lv2OPDMinTrq_Value: accessed-variable=VeDTMR_M_Lv2OPDMinTrq.Value
            OUT_VeDTMR_b_Lv2VehStndStillReq_FA_Value: accessed-variable=VeDTMR_b_Lv2VehStndStillReq_FA.Value
            OUT_VeDTMR_e_Lv2DrvMdRaw_Value: accessed-variable=VeDTMR_e_Lv2DrvMdRaw.Value
            OUT_VeDTMR_M_Lv2PtcWhlCcTrqReqRaw_Value: accessed-variable=VeDTMR_M_Lv2PtcWhlCcTrqReqRaw.Value
            OUT_VeDTMR_Pct_Lv2AccelPdlPosRaw_Value: accessed-variable=VeDTMR_Pct_Lv2AccelPdlPosRaw.Value
            OUT_VeDTMR_M_Lv2NormalMinTrqRaw_Value: accessed-variable=VeDTMR_M_Lv2NormalMinTrqRaw.Value
            OUT_VeDTMR_e_BrkPdlStat_Value: accessed-variable=VeDTMR_e_BrkPdlStat.Value
            OUT_VeDTMR_e_FaultSts_CM_Drv_TorqCalcPerf_Value: accessed-variable=VeDTMR_e_FaultSts_CM_Drv_TorqCalcPerf.Value
            OUT_VeDTMR_e_FaultSts_CM_OPDActivePerf_Value: accessed-variable=VeDTMR_e_FaultSts_CM_OPDActivePerf.Value
            OUT_VeDTMR_b_TransOutTrqCmdFlt_PN_Value: accessed-variable=VeDTMR_b_TransOutTrqCmdFlt_PN.Value
            OUT_VeDTMR_b_VehIn_Lv2LashCntrl_Value: accessed-variable=VeDTMR_b_VehIn_Lv2LashCntrl.Value
            OUT_VeDTMR_b_Lv2MaxRegenTorqDiff_FA_Value: accessed-variable=VeDTMR_b_Lv2MaxRegenTorqDiff_FA.Value
        sync call SC_DTMR_FastTEF_StartCheckpoint_CheckpointReached: operation=DTMR_FastTEF_StartCheckpoint.CheckpointReached, timeout=1E-06
        sync call SC_DTMR_FastTEF_StopCheckpoint_CheckpointReached: operation=DTMR_FastTEF_StopCheckpoint.CheckpointReached, timeout=1E-06
      runnable DTMR_PwrOn
        data-send-points:
          27 x access:
            OUT_VeDTMR_e_Lv2DrvMdRaw_Value: accessed-variable=VeDTMR_e_Lv2DrvMdRaw.Value
            OUT_VeDTMR_M_Lv2PtcWhlCcTrqReqRaw_Value: accessed-variable=VeDTMR_M_Lv2PtcWhlCcTrqReqRaw.Value
            OUT_VeDTMR_Pct_Lv2AccelPdlPosRaw_Value: accessed-variable=VeDTMR_Pct_Lv2AccelPdlPosRaw.Value
            OUT_VeDTMR_M_Lv2NormalMinTrqRaw_Value: accessed-variable=VeDTMR_M_Lv2NormalMinTrqRaw.Value
            OUT_VeDTMR_M_Lv2AccelPdlWhlTrq_Value: accessed-variable=VeDTMR_M_Lv2AccelPdlWhlTrq.Value
            OUT_VeDTMR_e_BrkPdlStat_Value: accessed-variable=VeDTMR_e_BrkPdlStat.Value
            OUT_VeDTMR_M_Lv2AxlTrqReq_Value: accessed-variable=VeDTMR_M_Lv2AxlTrqReq.Value
            OUT_VeDTMR_b_Lv2DsblAccelPdlRelatedMntr_Value: accessed-variable=VeDTMR_b_Lv2DsblAccelPdlRelatedMntr.Value
            OUT_VeDTMR_b_Lv2MaxLimFail_RedPerf_Value: accessed-variable=VeDTMR_b_Lv2MaxLimFail_RedPerf.Value
            OUT_VeDTMR_b_Lv2MinLimFail_RedPerf_Value: accessed-variable=VeDTMR_b_Lv2MinLimFail_RedPerf.Value
            OUT_VeDTMR_b_Lv2ReducedPerfMode_DTRChk_Value: accessed-variable=VeDTMR_b_Lv2ReducedPerfMode_DTRChk.Value
            OUT_VeDTMR_M_Lv2ReducedPrfmTrq_DTRChk_Value: accessed-variable=VeDTMR_M_Lv2ReducedPrfmTrq_DTRChk.Value
            OUT_VeDTMR_b_DTRcmdFlt_Value: accessed-variable=VeDTMR_b_DTRcmdFlt.Value
            OUT_VeDTMR_M_Lv2DriverTorqueReqstSTMR_Value: accessed-variable=VeDTMR_M_Lv2DriverTorqueReqstSTMR.Value
            OUT_VeDTMR_b_Lv2OPD_Selection_Value: accessed-variable=VeDTMR_b_Lv2OPD_Selection.Value
            OUT_VeDTMR_b_Lv2OPDInhibit_Value: accessed-variable=VeDTMR_b_Lv2OPDInhibit.Value
            OUT_VeDTMR_b_Lv2OPDInhibitHMI_Value: accessed-variable=VeDTMR_b_Lv2OPDInhibitHMI.Value
            OUT_VeDTMR_b_Lv2_OPD_ON_FA_Value: accessed-variable=VeDTMR_b_Lv2_OPD_ON_FA.Value
            OUT_VeDTMR_b_Lv2_OPD_ON_Value: accessed-variable=VeDTMR_b_Lv2_OPD_ON.Value
            OUT_VeDTMR_b_Lv2OPD_EnblCmnd_Value: accessed-variable=VeDTMR_b_Lv2OPD_EnblCmnd.Value
            OUT_VeDTMR_M_Lv2OPDMinTrq_Value: accessed-variable=VeDTMR_M_Lv2OPDMinTrq.Value
            OUT_VeDTMR_b_Lv2VehStndStillReq_FA_Value: accessed-variable=VeDTMR_b_Lv2VehStndStillReq_FA.Value
            OUT_VeDTMR_e_FaultSts_CM_Drv_TorqCalcPerf_Value: accessed-variable=VeDTMR_e_FaultSts_CM_Drv_TorqCalcPerf.Value
            OUT_VeDTMR_e_FaultSts_CM_OPDActivePerf_Value: accessed-variable=VeDTMR_e_FaultSts_CM_OPDActivePerf.Value
            OUT_VeDTMR_b_TransOutTrqCmdFlt_PN_Value: accessed-variable=VeDTMR_b_TransOutTrqCmdFlt_PN.Value
            OUT_VeDTMR_b_VehIn_Lv2LashCntrl_Value: accessed-variable=VeDTMR_b_VehIn_Lv2LashCntrl.Value
            OUT_VeDTMR_b_Lv2MaxRegenTorqDiff_FA_Value: accessed-variable=VeDTMR_b_Lv2MaxRegenTorqDiff_FA.Value
      6 x variation point proxy, all with category=CONDITION:
        Variant_DTMR_FUNC_1: condition-access=0
        Variant_DTMR_FUNC_2: condition-access=1
        Variant_DTMR_FUNC_{3..6}: condition-access=0
